# SIM3L167_C register map
File version: 1
256K Flash, 32K RAM, LCD, 80 PIN
CPU: 
Registers are 32-bit, read-write, reset 0x0 unless marked. A register's access mark holds for its fields unless they carry their own. Offsets are from the block's base; lines under a group give offsets from that group; [hi:lo] are bit positions; {n}, {i} and the like mark numbered series; 'fields as' and 'values as' point back to an identical list; <NAME> marks a mode.

## Memory map
0x40000000 USART_0 size 0xFFC
0x40001000 UART_0 size 0xFFC
0x40004000 SPI_0 size 0xFFC
0x40005000 SPI_1 size 0xFFC
0x40009000 I2C_0 size 0xFFC
0x4000E000 EPCA_0 size 0xFFC
0x40014000 TIMER_0 size 0xFFC
0x40015000 TIMER_1 size 0xFFC
0x40016000 TIMER_2 size 0xFFC
0x4001A000 SARADC_0 size 0xFFC
0x4001F000 CMP_0 size 0xFFC
0x40020000 CMP_1 size 0xFFC
0x40027000 AES_0 size 0xFFC
0x40028000 ECRC_0 size 0xFFC
0x40029000 RTC_0 size 0xFFC
0x4002A000 PBCFG_0 size 0xFFC
0x4002A0A0 PBSTD_0 size 0xFFC
0x4002A140 PBSTD_1 size 0xFFC
0x4002A1E0 PBSTD_2 size 0xFFC
0x4002A280 PBSTD_3 size 0xFFC
0x4002A320 PBGP_4 size 0xFFC
0x4002C000 RSTSRC_0 size 0xFFC
0x4002D000 CLKCTRL_0 size 0xFFC
0x4002E000 FLASHCTRL_0 size 0xFFC
0x4002F000 VMON_0 size 0xFFC
0x40030000 WDTIMER_0 size 0xFFC
0x40031000 IDAC_0 size 0xFFC
0x40036000 DMACTRL_0 size 0xFFC
0x40037000 DMAXBAR_0 size 0xFFC
0x40038000 LPTIMER_0 size 0xFFC
0x40039000 LDO_0 size 0xFFC
0x40039010 VREF_0 size 0xFFC
0x4003B000 PLL_0 size 0xFFC
0x4003C000 EXTOSC_0 size 0xFFC
0x4003D000 PVTOSC_0 size 0xFFC
0x40041000 LPOSC_0 size 0xFFC
0x40042000 ACCTR_0 size 0xFFC
0x40048000 PMU_0 size 0xFFC
0x40049000 LOCK_0 size 0xFFC
0x400490B0 SCONFIG_0 size 0xFFC
0x400490C0 DEVICEID_0 size 0xFFC
0x4004A000 DTM_0 size 0xFFC
0x4004B000 DTM_1 size 0xFFC
0x4004C000 DTM_2 size 0xFFC
0x4004D000 LCD_0 size 0xFFC
0x4004E000 DCDC_0 size 0xFFC
0x4004F000 ENCDEC_0 size 0xFFC

## Interrupts
0 WDTIMER0_IRQn (WDTIMER_0)
1 PBEXT0_IRQn (PBCFG_0)
2 PBEXT1_IRQn (PBCFG_0)
3 RTC0ALRM_IRQn (RTC_0)
4 LPTIMER0_IRQn (LPTIMER_0)
5 DMAERR_IRQn (DMAXBAR_0)
{n+6} DMACH{n}_IRQn (DMAXBAR_0) (n=0..9)
16 TIMER0L_IRQn (TIMER_0)
17 TIMER0H_IRQn (TIMER_0)
18 TIMER1L_IRQn (TIMER_1)
19 TIMER1H_IRQn (TIMER_1)
20 TIMER2L_IRQn (TIMER_2)
21 TIMER2H_IRQn (TIMER_2)
22 ACCTR0_IRQn (ACCTR_0)
23 EPCA0_IRQn (EPCA_0)
24 USART0_IRQn (USART_0)
25 UART0_IRQn (UART_0)
26 SPI0_IRQn (SPI_0)
27 SPI1_IRQn (SPI_1)
28 I2C0_IRQn (I2C_0)
29 SARADC0_IRQn (SARADC_0)
30 CMP0_IRQn (CMP_0)
31 CMP1_IRQn (CMP_1)
32 DTM0_IRQn (DTM_0)
33 DTM1_IRQn (DTM_1)
34 DTM2_IRQn (DTM_2)
35 AES0_IRQn (AES_0)
36 ENDEC0_IRQn (ENCDEC_0)
37 RTC0FAIL_IRQn (RTC_0)
38 VDDLOW_IRQn (VMON_0)
39 CPFAIL_IRQn (PMU_0)
40 DCDC_IRQn (DCDC_0)
41 PMATCH_IRQn (PBCFG_0)
42 IDAC0_IRQn (IDAC_0)
43 PLL0_IRQn (PLL_0)

## DEVICEID_0
Base 0x400490C0
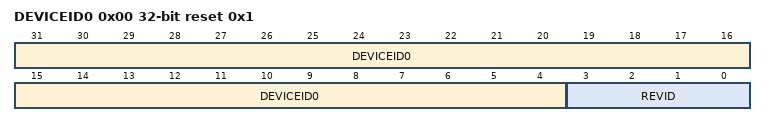
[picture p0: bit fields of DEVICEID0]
0x00 DEVICEID0 reset 0x1 — Device ID Word 0
  [31:4] DEVICEID0
  [3:0] REVID — Revision ID.
    0=REVA (Revision A.); 1=REVB (Revision B.); 2=REVC (Revision C.)
{0x0+0x10*i} DEVICEID{i} (i=1..3) — Device ID Word {i}

## ECRC_0
Base 0x40028000
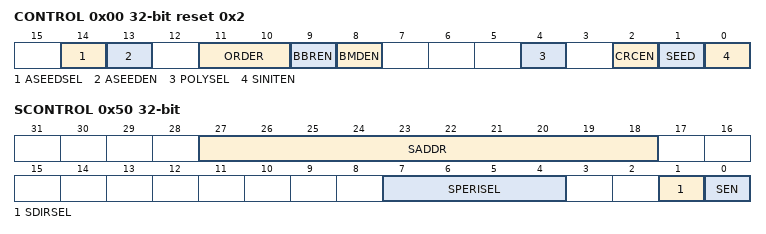
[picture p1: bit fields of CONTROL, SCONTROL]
0x00 CONTROL reset 0x2 — Module Control
  [14] ASEEDSEL — Automatic Seed Byte Select.
    0=LSB_READ (Select a read of the least-significant byte ([7:0]) of DATA, RDATA or BRDATA for automatic re-seeding.); 1=MSB_READ (Select a read of the most-significant byte [31:24] for 32-bit operations, and [15:8] for 16-bit operations) of DATA, RDATA or BRDATA for automatic re-seeding.)
  [13] ASEEDEN — Automatic Seed Enable.
    0=DISABLED (Disable automatic seeding.); 1=ENABLED (Enable automatic seeding. Reading the byte of the DATA register selected by ASEEDSEL re-seeds the CRC result with the setting selected by SEED.)
  [11:10] ORDER — Input Processing Order.
    0=NO_REORDER (No byte reorientation (output is same order as input).); 1=BIG_ENDIAN_16 (Swap for 16-bit big endian order (input: B3 B2 B1 B0, output: B2 B3 B0 B1).); 2=BIG_ENDIAN_32 (Swap for 32-bit big endian order (input: B3 B2 B1 B0, output: B0 B1 B2 B3).)
  [9] BBREN — Byte-Level Bit Reversal Enable.
    0=DISABLED (No byte-level bit reversal (input is same order as written).); 1=ENABLED (Byte-level bit reversal enabled (the bits in each byte are reversed).)
  [8] BMDEN — Byte Mode Enable.
    0=DISABLED (Disable byte mode (word/byte width is determined automatically by the hardware).); 1=ENABLED (Enable byte mode (all writes are considered as bytes).)
  [4] POLYSEL — Polynomial Selection.
    0=CRC32_FIXED (Select the fixed 32-bit polynomial: 0x04C11DB7.); 1=CRC16_PROG (Select the programmable 16-bit polynomial. The POLY register sets the polynomial coefficients.)
  [2] CRCEN — CRC Enable.
    0=DISABLED (Disable CRC operations.); 1=ENABLED (Enable CRC operations.)
  [1] SEED — Seed Setting.
    0=ALL_ZEROES (CRC seed value is all 0's (0x00000000)); 1=ALL_ONES (CRC seed value is all 1's (0xFFFFFFFF).)
  [0] SINITEN wo — Seed Initialization Enable.
    0=DISABLED (Do not initialize the CRC module to the value set by the SEED bit.); 1=ENABLED (Initialize the CRC module to the value set by the SEED bit.)
0x10 POLY reset 0x1021 — 16-bit Programmable Polynomial
  [15:0] POLY — 16-bit Programmable Polynomial.
0x20 DATA reset 0xFFFFFFFF — Input/Result Data
  [31:0] DATA — Input/Result Data.
0x30 RDATA reset 0xFFFFFFFF — Bit-Reversed Output Data
  [31:0] RDATA ro — Bit-Reversed Output Data.
0x40 BRDATA reset 0xFFFFFFFF — Byte-Reversed Output Data
  [31:0] BRDATA ro — Byte-Reversed Output Data.
0x50 SCONTROL — Bus Snooping Control
  [27:18] SADDR — Snooping Address.
  [7:4] SPERISEL — Snooping Peripheral Select.
  [1] SDIRSEL — Snooping Direction Select.
    0=WRITES (ECRC will snoop writes to the selected peripheral.); 1=READS (ECRC will snoop reads from the selected peripheral.)
  [0] SEN — Snooping Enable.
    0=DISABLED (Disable automatic bus snooping.); 1=ENABLED (Enable automatic bus snooping.)
